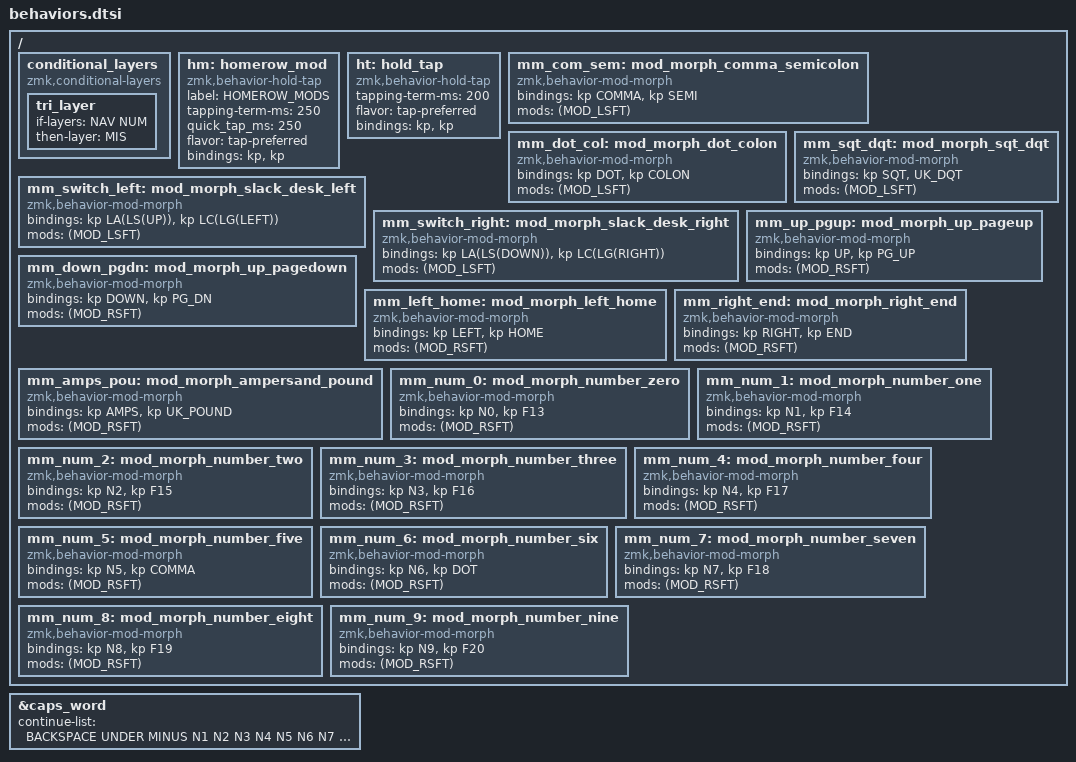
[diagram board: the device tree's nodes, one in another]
&caps_word	{ continue-list = <BACKSPACE UNDER MINUS N1 N2 N3 N4 N5 N6 N7 N8 N9 N0>; };

/ {	
	/******************** LAYERS ************************/	
	conditional_layers {
		compatible = "zmk,conditional-layers";
		tri_layer {
			if-layers = <NAV NUM>;
			then-layer = <MIS>;
		};
	};

	/******************** HOLD TAPS *********************/
	hm: homerow_mod {
		compatible = "zmk,behavior-hold-tap";
		label = "HOMEROW_MODS";
		#binding-cells = <2>;
		tapping-term-ms = <250>;
		quick_tap_ms = <250>;
		flavor = "tap-preferred";
		bindings = <&kp>, <&kp>;
	};

	ht: hold_tap {
		compatible = "zmk,behavior-hold-tap";
		#binding-cells = <2>;
		tapping-term-ms = <200>;
		flavor = "tap-preferred";
		bindings = <&kp>, <&kp>;
	};

	/******************** MOD MORPHS ********************/
	mm_com_sem: mod_morph_comma_semicolon {
		compatible = "zmk,behavior-mod-morph";
		#binding-cells = <0>;
		bindings = <&kp COMMA>, <&kp SEMI>;
		mods = <(MOD_LSFT)>;
	};

	mm_dot_col: mod_morph_dot_colon {
		compatible = "zmk,behavior-mod-morph";
		#binding-cells = <0>;
		bindings = <&kp DOT>, <&kp COLON>;
		mods = <(MOD_LSFT)>;
	};

	mm_switch_left: mod_morph_slack_desk_left {
		compatible = "zmk,behavior-mod-morph";
		#binding-cells = <0>;
		bindings = <&kp LA(LS(UP))>, <&kp LC(LG(LEFT))>;
		mods = <(MOD_LSFT)>;
	};

	mm_switch_right: mod_morph_slack_desk_right {
		compatible = "zmk,behavior-mod-morph";
		#binding-cells = <0>;
		bindings = <&kp LA(LS(DOWN))>, <&kp LC(LG(RIGHT))>;
		mods = <(MOD_LSFT)>;
	};

	mm_sqt_dqt: mod_morph_sqt_dqt {
		compatible = "zmk,behavior-mod-morph";
		#binding-cells = <0>;
		bindings = <&kp SQT>, <UK_DQT>;
		mods = <(MOD_LSFT)>;
	};

	mm_up_pgup: mod_morph_up_pageup {
		compatible = "zmk,behavior-mod-morph";
		#binding-cells = <0>;
		bindings = <&kp UP>, <&kp PG_UP>;
		mods = <(MOD_RSFT)>;
	};

	mm_down_pgdn: mod_morph_up_pagedown {
		compatible = "zmk,behavior-mod-morph";
		#binding-cells = <0>;
		bindings = <&kp DOWN>, <&kp PG_DN>;
		mods = <(MOD_RSFT)>;
	};

	mm_left_home: mod_morph_left_home {
		compatible = "zmk,behavior-mod-morph";
		#binding-cells = <0>;
		bindings = <&kp LEFT>, <&kp HOME>;
		mods = <(MOD_RSFT)>;
	};

	mm_right_end: mod_morph_right_end {
		compatible = "zmk,behavior-mod-morph";
		#binding-cells = <0>;
		bindings = <&kp RIGHT>, <&kp END>;
		mods = <(MOD_RSFT)>;
	};

	mm_amps_pou: mod_morph_ampersand_pound {
		compatible = "zmk,behavior-mod-morph";
		#binding-cells = <0>;
		bindings = <&kp AMPS>, <&kp UK_POUND>;
		mods = <(MOD_RSFT)>;		
	};

	mm_num_0: mod_morph_number_zero {
		compatible = "zmk,behavior-mod-morph";
		#binding-cells = <0>;
		bindings = <&kp N0>, <&kp F13>;
		mods = <(MOD_RSFT)>;
	};

	mm_num_1: mod_morph_number_one {
		compatible = "zmk,behavior-mod-morph";
		#binding-cells = <0>;
		bindings = <&kp N1>, <&kp F14>;
		mods = <(MOD_RSFT)>;
	};

	mm_num_2: mod_morph_number_two {
		compatible = "zmk,behavior-mod-morph";
		#binding-cells = <0>;
		bindings = <&kp N2>, <&kp F15>;
		mods = <(MOD_RSFT)>;
	};

	mm_num_3: mod_morph_number_three {
		compatible = "zmk,behavior-mod-morph";
		#binding-cells = <0>;
		bindings = <&kp N3>, <&kp F16>;
		mods = <(MOD_RSFT)>;
	};

	mm_num_4: mod_morph_number_four {
		compatible = "zmk,behavior-mod-morph";
		#binding-cells = <0>;
		bindings = <&kp N4>, <&kp F17>;
		mods = <(MOD_RSFT)>;
	};

	mm_num_5: mod_morph_number_five {
		compatible = "zmk,behavior-mod-morph";
		#binding-cells = <0>;
		bindings = <&kp N5>, <&kp COMMA>;
		mods = <(MOD_RSFT)>;
	};

	mm_num_6: mod_morph_number_six {
		compatible = "zmk,behavior-mod-morph";
		#binding-cells = <0>;
		bindings = <&kp N6>, <&kp DOT>;
		mods = <(MOD_RSFT)>;
	};

	mm_num_7: mod_morph_number_seven {
		compatible = "zmk,behavior-mod-morph";
		#binding-cells = <0>;
		bindings = <&kp N7>, <&kp F18>;
		mods = <(MOD_RSFT)>;
	};

	mm_num_8: mod_morph_number_eight {
		compatible = "zmk,behavior-mod-morph";
		#binding-cells = <0>;
		bindings = <&kp N8>, <&kp F19>;
		mods = <(MOD_RSFT)>;
	};

	mm_num_9: mod_morph_number_nine {
		compatible = "zmk,behavior-mod-morph";
		#binding-cells = <0>;
		bindings = <&kp N9>, <&kp F20>;
		mods = <(MOD_RSFT)>;
	};
};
